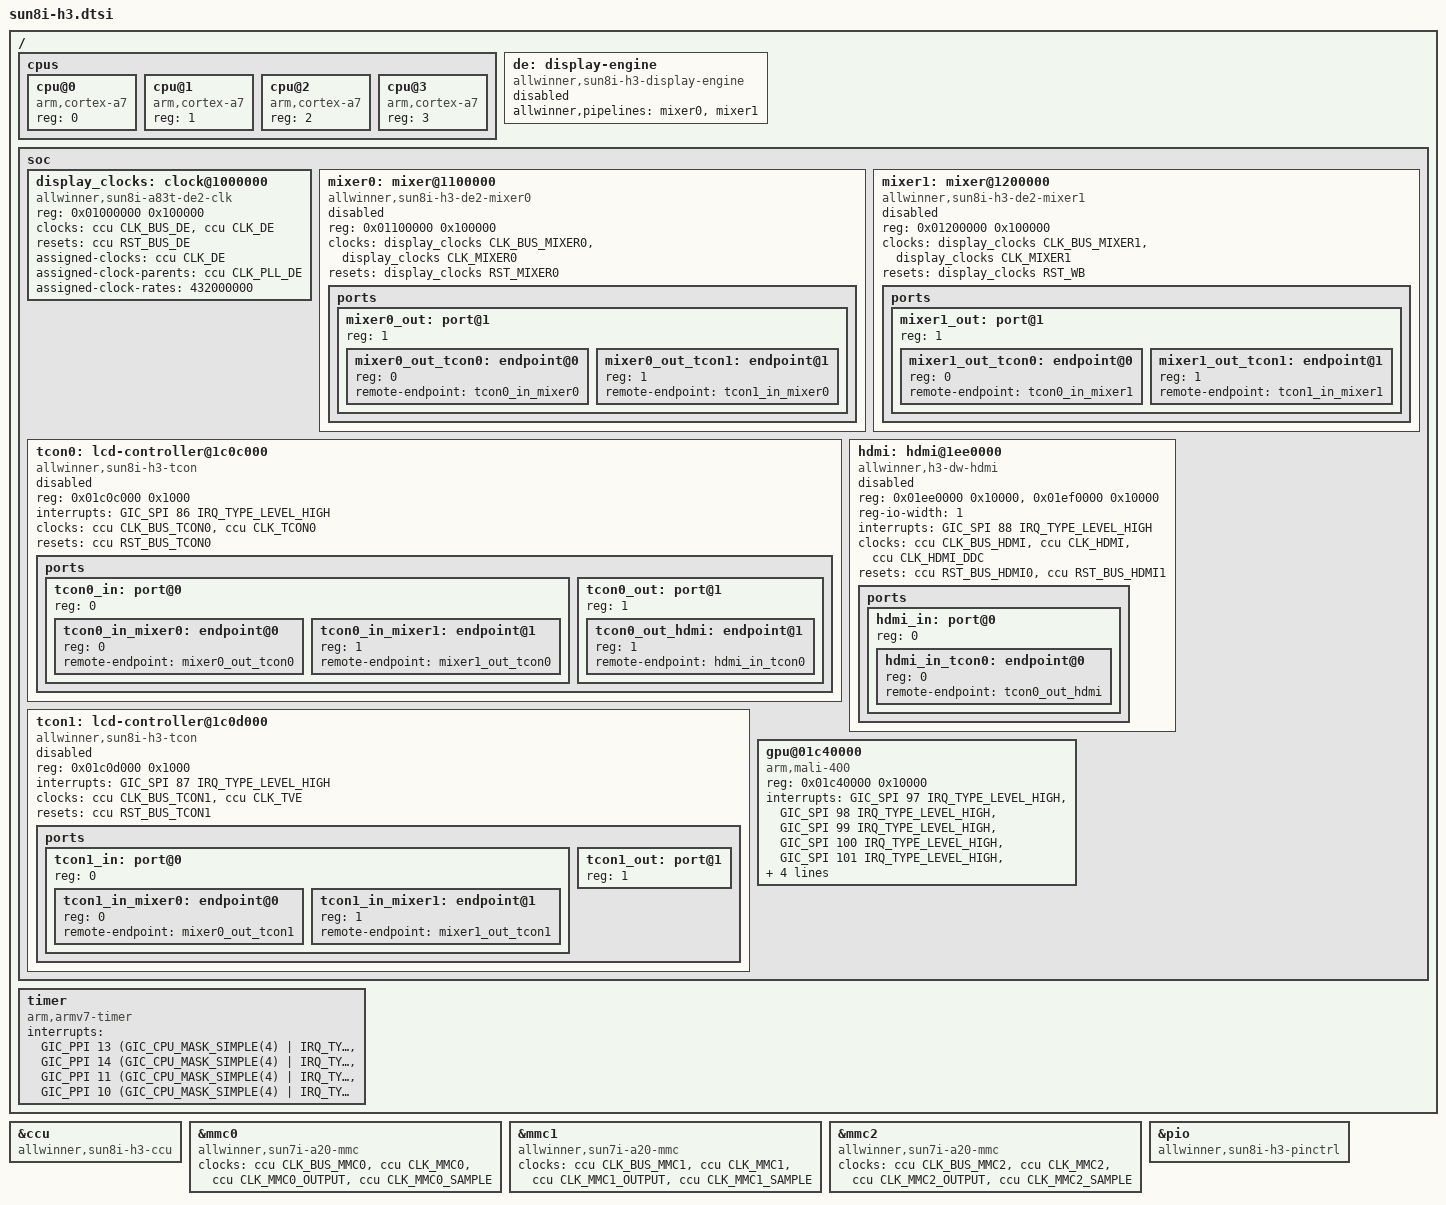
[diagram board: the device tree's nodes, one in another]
/*
 * Copyright (C) 2015 Jens Kuske <jenskuske@gmail.com>
 *
 * This file is dual-licensed: you can use it either under the terms
 * of the GPL or the X11 license, at your option. Note that this dual
 * licensing only applies to this file, and not this project as a
 * whole.
 *
 *  a) This file is free software; you can redistribute it and/or
 *     modify it under the terms of the GNU General Public License as
 *     published by the Free Software Foundation; either version 2 of the
 *     License, or (at your option) any later version.
 *
 *     This file is distributed in the hope that it will be useful,
 *     but WITHOUT ANY WARRANTY; without even the implied warranty of
 *     MERCHANTABILITY or FITNESS FOR A PARTICULAR PURPOSE.  See the
 *     GNU General Public License for more details.
 *
 * Or, alternatively,
 *
 *  b) Permission is hereby granted, free of charge, to any person
 *     obtaining a copy of this software and associated documentation
 *     files (the "Software"), to deal in the Software without
 *     restriction, including without limitation the rights to use,
 *     copy, modify, merge, publish, distribute, sublicense, and/or
 *     sell copies of the Software, and to permit persons to whom the
 *     Software is furnished to do so, subject to the following
 *     conditions:
 *
 *     The above copyright notice and this permission notice shall be
 *     included in all copies or substantial portions of the Software.
 *
 *     THE SOFTWARE IS PROVIDED "AS IS", WITHOUT WARRANTY OF ANY KIND,
 *     EXPRESS OR IMPLIED, INCLUDING BUT NOT LIMITED TO THE WARRANTIES
 *     OF MERCHANTABILITY, FITNESS FOR A PARTICULAR PURPOSE AND
 *     NONINFRINGEMENT. IN NO EVENT SHALL THE AUTHORS OR COPYRIGHT
 *     HOLDERS BE LIABLE FOR ANY CLAIM, DAMAGES OR OTHER LIABILITY,
 *     WHETHER IN AN ACTION OF CONTRACT, TORT OR OTHERWISE, ARISING
 *     FROM, OUT OF OR IN CONNECTION WITH THE SOFTWARE OR THE USE OR
 *     OTHER DEALINGS IN THE SOFTWARE.
 */

#include "sunxi-h3-h5.dtsi"
#include <dt-bindings/clock/sun8i-de2.h>
#include <dt-bindings/reset/sun8i-de2.h>

/ {
	cpus {
		#address-cells = <1>;
		#size-cells = <0>;

		cpu@0 {
			compatible = "arm,cortex-a7";
			device_type = "cpu";
			reg = <0>;
		};

		cpu@1 {
			compatible = "arm,cortex-a7";
			device_type = "cpu";
			reg = <1>;
		};

		cpu@2 {
			compatible = "arm,cortex-a7";
			device_type = "cpu";
			reg = <2>;
		};

		cpu@3 {
			compatible = "arm,cortex-a7";
			device_type = "cpu";
			reg = <3>;
		};
	};

	de: display-engine {
		compatible = "allwinner,sun8i-h3-display-engine";
		allwinner,pipelines = <&mixer0>,
				      <&mixer1>;
		status = "disabled";
	};

	soc {
		display_clocks: clock@1000000 {
			compatible = "allwinner,sun8i-a83t-de2-clk";
			reg = <0x01000000 0x100000>;
			clocks = <&ccu CLK_BUS_DE>,
				 <&ccu CLK_DE>;
			clock-names = "bus",
				      "mod";
			resets = <&ccu RST_BUS_DE>;
			#clock-cells = <1>;
			#reset-cells = <1>;
			assigned-clocks = <&ccu CLK_DE>;
			assigned-clock-parents = <&ccu CLK_PLL_DE>;
			assigned-clock-rates = <432000000>;
		};

		mixer0: mixer@1100000 {
			compatible = "allwinner,sun8i-h3-de2-mixer0";
			reg = <0x01100000 0x100000>;
			clocks = <&display_clocks CLK_BUS_MIXER0>,
				 <&display_clocks CLK_MIXER0>;
			clock-names = "bus",
				      "mod";
			resets = <&display_clocks RST_MIXER0>;
			status = "disabled";

			ports {
				#address-cells = <1>;
				#size-cells = <0>;

				mixer0_out: port@1 {
					#address-cells = <1>;
					#size-cells = <0>;
					reg = <1>;

					mixer0_out_tcon0: endpoint@0 {
						reg = <0>;
						remote-endpoint = <&tcon0_in_mixer0>;
					};

					mixer0_out_tcon1: endpoint@1 {
						reg = <1>;
						remote-endpoint = <&tcon1_in_mixer0>;
					};
				};
			};
		};

		mixer1: mixer@1200000 {
			compatible = "allwinner,sun8i-h3-de2-mixer1";
			reg = <0x01200000 0x100000>;
			clocks = <&display_clocks CLK_BUS_MIXER1>,
				 <&display_clocks CLK_MIXER1>;
			clock-names = "bus",
				      "mod";
			resets = <&display_clocks RST_WB>;
			status = "disabled";

			ports {
				#address-cells = <1>;
				#size-cells = <0>;

				mixer1_out: port@1 {
					#address-cells = <1>;
					#size-cells = <0>;
					reg = <1>;

					mixer1_out_tcon0: endpoint@0 {
						reg = <0>;
						remote-endpoint = <&tcon0_in_mixer1>;
					};

					mixer1_out_tcon1: endpoint@1 {
						reg = <1>;
						remote-endpoint = <&tcon1_in_mixer1>;
					};
				};
			};
		};

		tcon0: lcd-controller@1c0c000 {
			compatible = "allwinner,sun8i-h3-tcon";
			reg = <0x01c0c000 0x1000>;
			interrupts = <GIC_SPI 86 IRQ_TYPE_LEVEL_HIGH>;
			clocks = <&ccu CLK_BUS_TCON0>,
				 <&ccu CLK_TCON0>;
			clock-names = "ahb",
				      "tcon-ch1";
			resets = <&ccu RST_BUS_TCON0>;
			reset-names = "lcd";
			status = "disabled";

			ports {
				#address-cells = <1>;
				#size-cells = <0>;

				tcon0_in: port@0 {
					#address-cells = <1>;
					#size-cells = <0>;
					reg = <0>;

					tcon0_in_mixer0: endpoint@0 {
						reg = <0>;
						remote-endpoint = <&mixer0_out_tcon0>;
					};

					tcon0_in_mixer1: endpoint@1 {
						reg = <1>;
						remote-endpoint = <&mixer1_out_tcon0>;
					};
				};

				tcon0_out: port@1 {
					#address-cells = <1>;
					#size-cells = <0>;
					reg = <1>;

					tcon0_out_hdmi: endpoint@1 {
						reg = <1>;
						remote-endpoint = <&hdmi_in_tcon0>;
					};
				};
			};
		};

		tcon1: lcd-controller@1c0d000 {
			compatible = "allwinner,sun8i-h3-tcon";
			reg = <0x01c0d000 0x1000>;
			interrupts = <GIC_SPI 87 IRQ_TYPE_LEVEL_HIGH>;
			clocks = <&ccu CLK_BUS_TCON1>,
				 <&ccu CLK_TVE>;
			clock-names = "ahb",
				      "tcon-ch1";
			resets = <&ccu RST_BUS_TCON1>;
			reset-names = "lcd";
			status = "disabled";

			ports {
				#address-cells = <1>;
				#size-cells = <0>;

				tcon1_in: port@0 {
					#address-cells = <1>;
					#size-cells = <0>;
					reg = <0>;

					tcon1_in_mixer0: endpoint@0 {
						reg = <0>;
						remote-endpoint = <&mixer0_out_tcon1>;
					};

					tcon1_in_mixer1: endpoint@1 {
						reg = <1>;
						remote-endpoint = <&mixer1_out_tcon1>;
					};
				};

				tcon1_out: port@1 {
					#address-cells = <1>;
					#size-cells = <0>;
					reg = <1>;
				};
			};
		};

		hdmi: hdmi@1ee0000 {
			compatible = "allwinner,h3-dw-hdmi";
			reg = <0x01ee0000 0x10000>,
			      <0x01ef0000 0x10000>;
			reg-io-width = <1>;
			interrupts = <GIC_SPI 88 IRQ_TYPE_LEVEL_HIGH>;
			clocks = <&ccu CLK_BUS_HDMI>, <&ccu CLK_HDMI>,
				 <&ccu CLK_HDMI_DDC>;
			clock-names = "iahb", "isfr", "iddc";
			resets = <&ccu RST_BUS_HDMI0>, <&ccu RST_BUS_HDMI1>;
			reset-names = "hdmi", "ddc";
			status = "disabled";

			ports {
				#address-cells = <1>;
				#size-cells = <0>;

				hdmi_in: port@0 {
					#address-cells = <1>;
					#size-cells = <0>;
					reg = <0>;

					hdmi_in_tcon0: endpoint@0 {
						reg = <0>;
						remote-endpoint = <&tcon0_out_hdmi>;
					};
				};
			};
		};
	};

	timer {
		compatible = "arm,armv7-timer";
		interrupts = <GIC_PPI 13 (GIC_CPU_MASK_SIMPLE(4) | IRQ_TYPE_LEVEL_LOW)>,
			     <GIC_PPI 14 (GIC_CPU_MASK_SIMPLE(4) | IRQ_TYPE_LEVEL_LOW)>,
			     <GIC_PPI 11 (GIC_CPU_MASK_SIMPLE(4) | IRQ_TYPE_LEVEL_LOW)>,
			     <GIC_PPI 10 (GIC_CPU_MASK_SIMPLE(4) | IRQ_TYPE_LEVEL_LOW)>;
	};

	soc {
		gpu@01c40000 {
			compatible = "arm,mali-400";
			reg = <0x01c40000 0x10000>;
			interrupts = <GIC_SPI 97 IRQ_TYPE_LEVEL_HIGH>,
					   <GIC_SPI 98 IRQ_TYPE_LEVEL_HIGH>,
					   <GIC_SPI 99 IRQ_TYPE_LEVEL_HIGH>,
					   <GIC_SPI 100 IRQ_TYPE_LEVEL_HIGH>,
					   <GIC_SPI 101 IRQ_TYPE_LEVEL_HIGH>,
					   <GIC_SPI 102 IRQ_TYPE_LEVEL_HIGH>,
					   <GIC_SPI 103 IRQ_TYPE_LEVEL_HIGH>;
			interrupt-names = "gp", "gpmmu", "pp0", "ppmmu0", "pmu",
					  "pp1", "ppmmu1";
			clocks = <&ccu CLK_BUS_GPU>, <&ccu CLK_GPU>;
			clock-names = "bus", "core";
			resets = <&ccu RST_BUS_GPU>;
		};
	};
};

&ccu {
	compatible = "allwinner,sun8i-h3-ccu";
};

&mmc0 {
	compatible = "allwinner,sun7i-a20-mmc";
	clocks = <&ccu CLK_BUS_MMC0>,
		 <&ccu CLK_MMC0>,
		 <&ccu CLK_MMC0_OUTPUT>,
		 <&ccu CLK_MMC0_SAMPLE>;
	clock-names = "ahb",
		      "mmc",
		      "output",
		      "sample";
};

&mmc1 {
	compatible = "allwinner,sun7i-a20-mmc";
	clocks = <&ccu CLK_BUS_MMC1>,
		 <&ccu CLK_MMC1>,
		 <&ccu CLK_MMC1_OUTPUT>,
		 <&ccu CLK_MMC1_SAMPLE>;
	clock-names = "ahb",
		      "mmc",
		      "output",
		      "sample";
};

&mmc2 {
	compatible = "allwinner,sun7i-a20-mmc";
	clocks = <&ccu CLK_BUS_MMC2>,
		 <&ccu CLK_MMC2>,
		 <&ccu CLK_MMC2_OUTPUT>,
		 <&ccu CLK_MMC2_SAMPLE>;
	clock-names = "ahb",
		      "mmc",
		      "output",
		      "sample";
};

&pio {
	compatible = "allwinner,sun8i-h3-pinctrl";
};
